# PIC32MZ2048EFM144 register map
Registers are 32-bit, access not given, reset 0x0 unless marked. A register's access mark holds for its fields unless they carry their own. Offsets are from the block's base; [hi:lo] are bit positions; {n}, {i} and the like mark numbered series; 'fields as' and 'values as' point back to an identical list.

## INT — INT peripheral
Base 0xBF810000
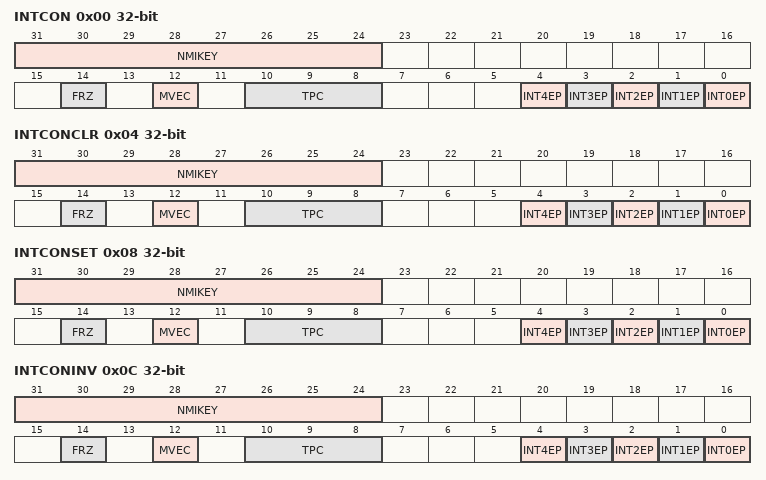
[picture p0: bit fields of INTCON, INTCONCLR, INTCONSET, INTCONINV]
0x00 INTCON
  [31:24] NMIKEY, [14] FRZ, [12] MVEC, [10:8] TPC, [n] INT{n}EP (n=0..4)
0x04 INTCONCLR
  fields as INTCON
0x08 INTCONSET
  fields as INTCON
0x0C INTCONINV
  fields as INTCON
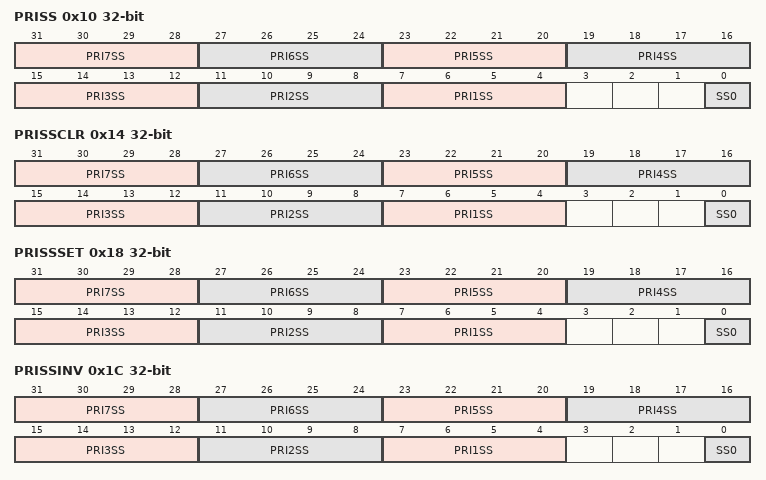
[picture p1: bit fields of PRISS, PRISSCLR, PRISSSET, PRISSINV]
0x10 PRISS
  [4n+3:4n] PRI{n}SS (n=1..7), [0] SS0
0x14 PRISSCLR
  [4n+3:4n] PRI{n}SS (n=1..7), [0] SS0
0x18 PRISSSET
  [4n+3:4n] PRI{n}SS (n=1..7), [0] SS0
0x1C PRISSINV
  [4n+3:4n] PRI{n}SS (n=1..7), [0] SS0
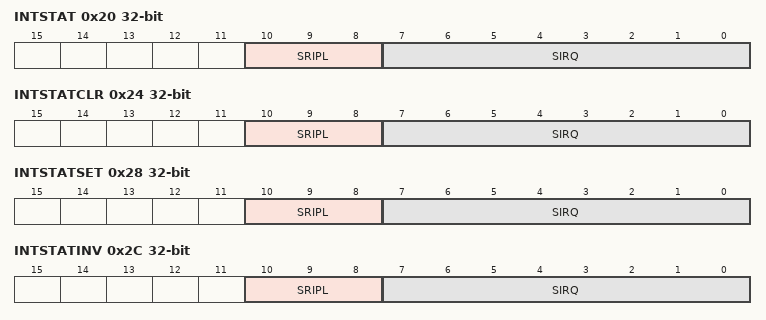
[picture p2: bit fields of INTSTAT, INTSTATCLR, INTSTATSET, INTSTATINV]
0x20 INTSTAT
  [10:8] SRIPL, [7:0] SIRQ
0x24 INTSTATCLR
  [10:8] SRIPL, [7:0] SIRQ
0x28 INTSTATSET
  [10:8] SRIPL, [7:0] SIRQ
0x2C INTSTATINV
  [10:8] SRIPL, [7:0] SIRQ
0x30 IPTMR
0x34 IPTMRCLR
  [31:0] IPTMR
0x38 IPTMRSET
  [31:0] IPTMR
0x3C IPTMRINV
  [31:0] IPTMR
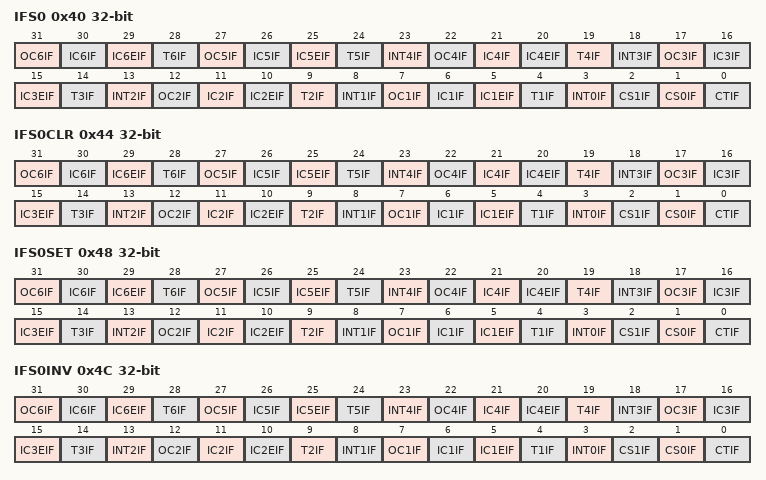
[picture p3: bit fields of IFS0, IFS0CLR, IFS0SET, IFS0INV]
0x40 IFS0
  [31] OC6IF, [30] IC6IF, [29] IC6EIF, [28] T6IF, [5n+2] OC{n}IF (n=1..5), [5n+1] IC{n}IF (n=1..5), [5n] IC{n}EIF (n=1..5), [5n-1] T{n}IF (n=1..5), [5n+3] INT{n}IF (n=0..4), [2] CS1IF, [1] CS0IF, [0] CTIF
0x44 IFS0CLR
  fields as IFS0
0x48 IFS0SET
  fields as IFS0
0x4C IFS0INV
  fields as IFS0
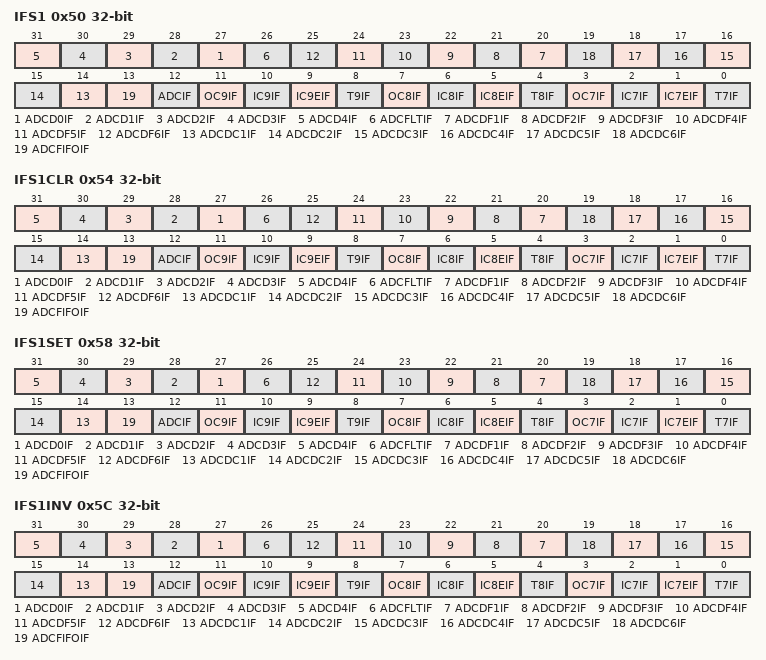
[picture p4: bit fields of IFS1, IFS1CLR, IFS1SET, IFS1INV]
0x50 IFS1
  [n+27] ADCD{n}IF (n=0..4), [26] ADCFLTIF, [n+19] ADCDF{n}IF (n=1..6), [n+13] ADCDC{n}IF (n=1..6), [13] ADCFIFOIF, [12] ADCIF, [11] OC9IF, [10] IC9IF, [9] IC9EIF, [8] T9IF, [7] OC8IF, [6] IC8IF, [5] IC8EIF, [4] T8IF, [3] OC7IF, [2] IC7IF, [1] IC7EIF, [0] T7IF
0x54 IFS1CLR
  fields as IFS1
0x58 IFS1SET
  fields as IFS1
0x5C IFS1INV
  fields as IFS1
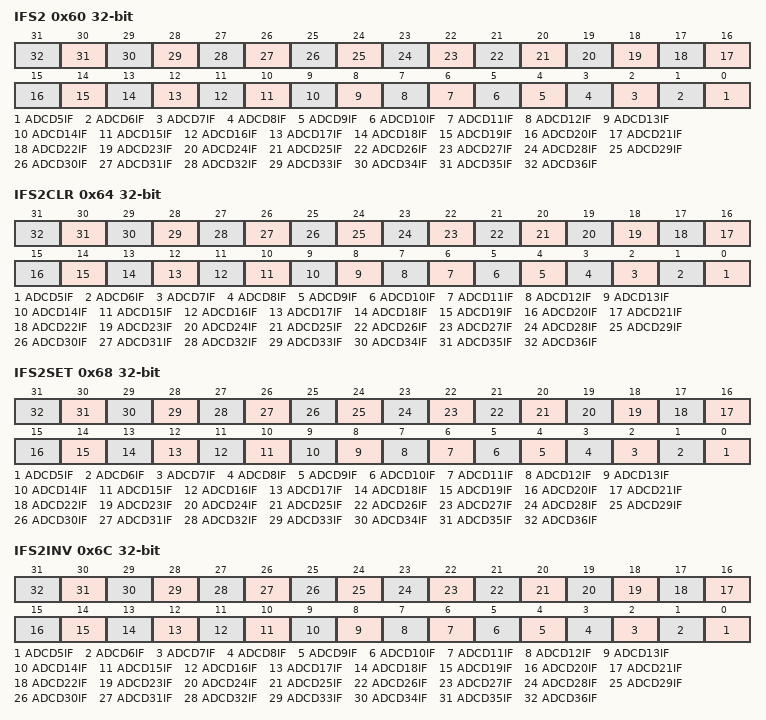
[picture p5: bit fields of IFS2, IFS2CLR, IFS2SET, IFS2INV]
0x60 IFS2
  [n-5] ADCD{n}IF (n=5..36)
0x64 IFS2CLR
  [n-5] ADCD{n}IF (n=5..36)
0x68 IFS2SET
  [n-5] ADCD{n}IF (n=5..36)
0x6C IFS2INV
  [n-5] ADCD{n}IF (n=5..36)
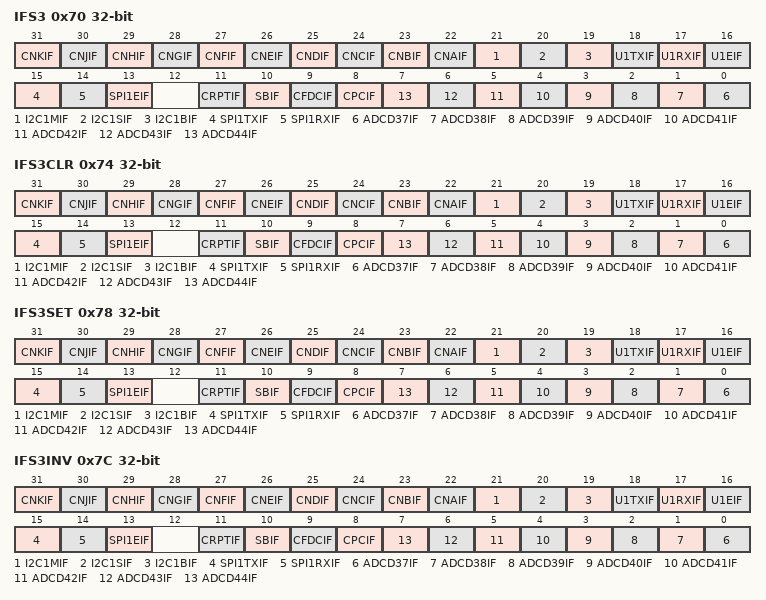
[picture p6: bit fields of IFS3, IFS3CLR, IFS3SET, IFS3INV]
0x70 IFS3
  [31] CNKIF, [30] CNJIF, [29] CNHIF, [28] CNGIF, [27] CNFIF, [26] CNEIF, [25] CNDIF, [24] CNCIF, [23] CNBIF, [22] CNAIF, [21] I2C1MIF, [20] I2C1SIF, [19] I2C1BIF, [18] U1TXIF, [17] U1RXIF, [16] U1EIF, [15] SPI1TXIF, [14] SPI1RXIF, [13] SPI1EIF, [11] CRPTIF, [10] SBIF, [9] CFDCIF, [8] CPCIF, [n-37] ADCD{n}IF (n=37..44)
0x74 IFS3CLR
  fields as IFS3
0x78 IFS3SET
  fields as IFS3
0x7C IFS3INV
  fields as IFS3
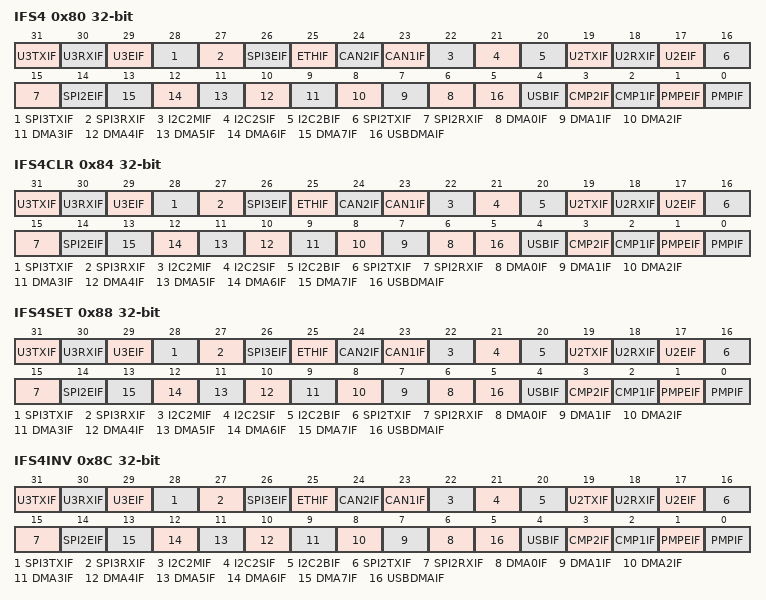
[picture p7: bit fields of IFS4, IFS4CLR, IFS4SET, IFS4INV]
0x80 IFS4
  [31] U3TXIF, [30] U3RXIF, [29] U3EIF, [28] SPI3TXIF, [27] SPI3RXIF, [26] SPI3EIF, [25] ETHIF, [24] CAN2IF, [23] CAN1IF, [22] I2C2MIF, [21] I2C2SIF, [20] I2C2BIF, [19] U2TXIF, [18] U2RXIF, [17] U2EIF, [16] SPI2TXIF, [15] SPI2RXIF, [14] SPI2EIF, [n+6] DMA{n}IF (n=0..7), [5] USBDMAIF, [4] USBIF, [3] CMP2IF, [2] CMP1IF, [1] PMPEIF, [0] PMPIF
0x84 IFS4CLR
  fields as IFS4
0x88 IFS4SET
  fields as IFS4
0x8C IFS4INV
  fields as IFS4
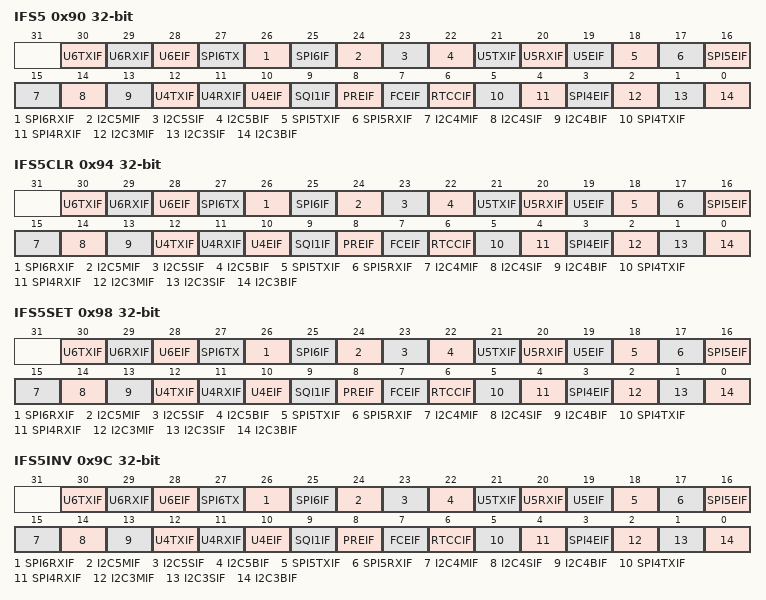
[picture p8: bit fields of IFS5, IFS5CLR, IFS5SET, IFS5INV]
0x90 IFS5
  [30] U6TXIF, [29] U6RXIF, [28] U6EIF, [27] SPI6TX, [26] SPI6RXIF, [25] SPI6IF, [24] I2C5MIF, [23] I2C5SIF, [22] I2C5BIF, [21] U5TXIF, [20] U5RXIF, [19] U5EIF, [18] SPI5TXIF, [17] SPI5RXIF, [16] SPI5EIF, [15] I2C4MIF, [14] I2C4SIF, [13] I2C4BIF, [12] U4TXIF, [11] U4RXIF, [10] U4EIF, [9] SQI1IF, [8] PREIF, [7] FCEIF, [6] RTCCIF, [5] SPI4TXIF, [4] SPI4RXIF, [3] SPI4EIF, [2] I2C3MIF, [1] I2C3SIF, [0] I2C3BIF
0x94 IFS5CLR
  fields as IFS5
0x98 IFS5SET
  fields as IFS5
0x9C IFS5INV
  fields as IFS5
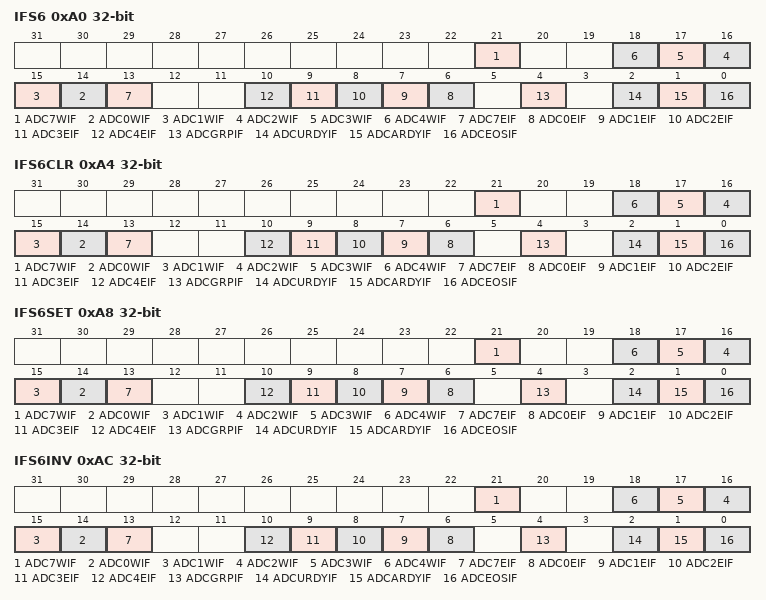
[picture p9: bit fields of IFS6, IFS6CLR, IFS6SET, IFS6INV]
0xA0 IFS6
  [21] ADC7WIF, [n+14] ADC{n}WIF (n=0..4), [13] ADC7EIF, [n+6] ADC{n}EIF (n=0..4), [4] ADCGRPIF, [2] ADCURDYIF, [1] ADCARDYIF, [0] ADCEOSIF
0xA4 IFS6CLR
  fields as IFS6
0xA8 IFS6SET
  fields as IFS6
0xAC IFS6INV
  fields as IFS6
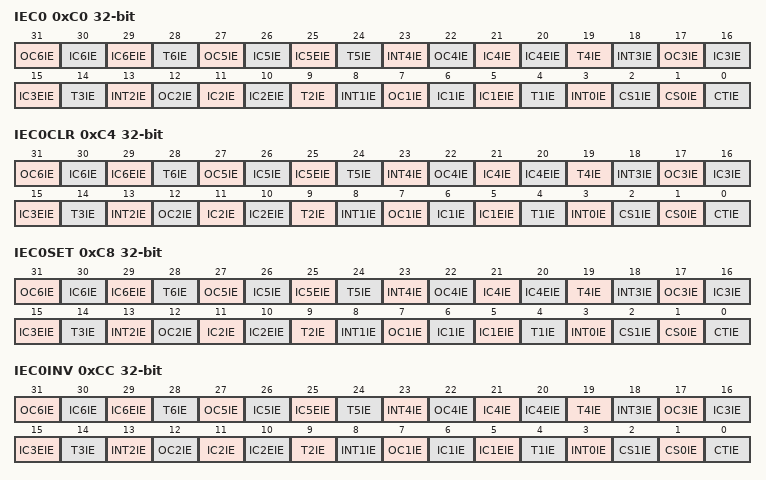
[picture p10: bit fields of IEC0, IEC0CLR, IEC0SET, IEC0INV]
0xC0 IEC0
  [31] OC6IE, [30] IC6IE, [29] IC6EIE, [28] T6IE, [5n+2] OC{n}IE (n=1..5), [5n+1] IC{n}IE (n=1..5), [5n] IC{n}EIE (n=1..5), [5n-1] T{n}IE (n=1..5), [5n+3] INT{n}IE (n=0..4), [2] CS1IE, [1] CS0IE, [0] CTIE
0xC4 IEC0CLR
  fields as IEC0
0xC8 IEC0SET
  fields as IEC0
0xCC IEC0INV
  fields as IEC0
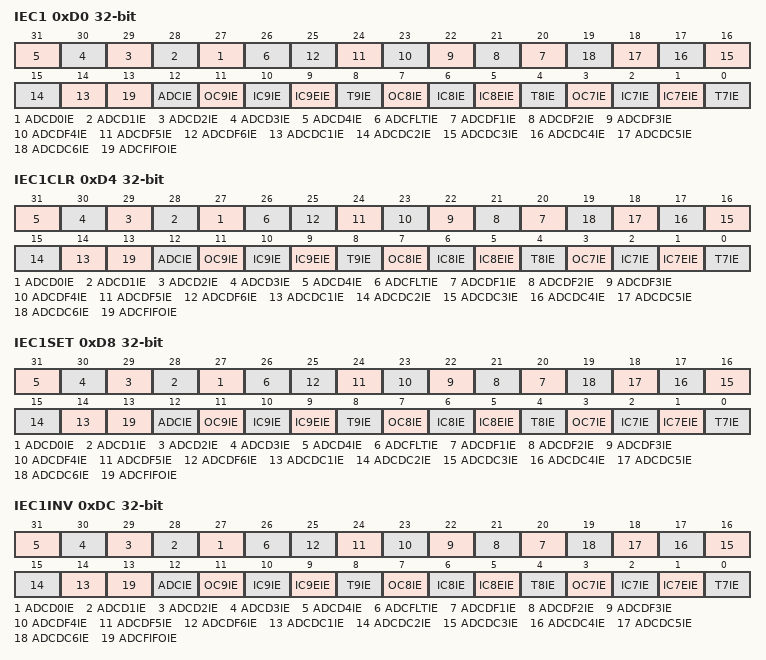
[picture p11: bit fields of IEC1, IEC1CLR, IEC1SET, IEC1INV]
0xD0 IEC1
  [n+27] ADCD{n}IE (n=0..4), [26] ADCFLTIE, [n+19] ADCDF{n}IE (n=1..6), [n+13] ADCDC{n}IE (n=1..6), [13] ADCFIFOIE, [12] ADCIE, [11] OC9IE, [10] IC9IE, [9] IC9EIE, [8] T9IE, [7] OC8IE, [6] IC8IE, [5] IC8EIE, [4] T8IE, [3] OC7IE, [2] IC7IE, [1] IC7EIE, [0] T7IE
0xD4 IEC1CLR
  fields as IEC1
0xD8 IEC1SET
  fields as IEC1
0xDC IEC1INV
  fields as IEC1
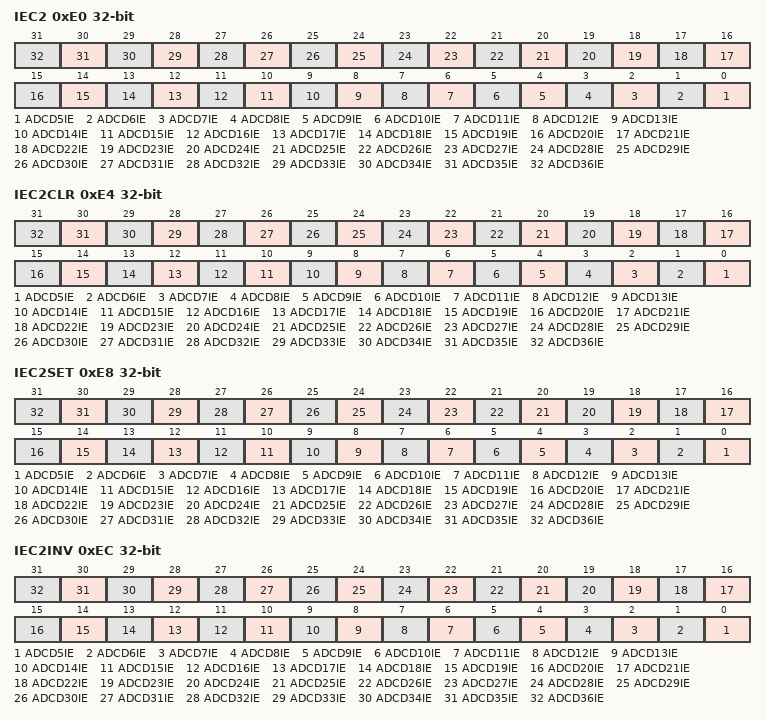
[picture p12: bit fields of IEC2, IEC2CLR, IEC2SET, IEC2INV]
0xE0 IEC2
  [n-5] ADCD{n}IE (n=5..36)
0xE4 IEC2CLR
  [n-5] ADCD{n}IE (n=5..36)
0xE8 IEC2SET
  [n-5] ADCD{n}IE (n=5..36)
0xEC IEC2INV
  [n-5] ADCD{n}IE (n=5..36)
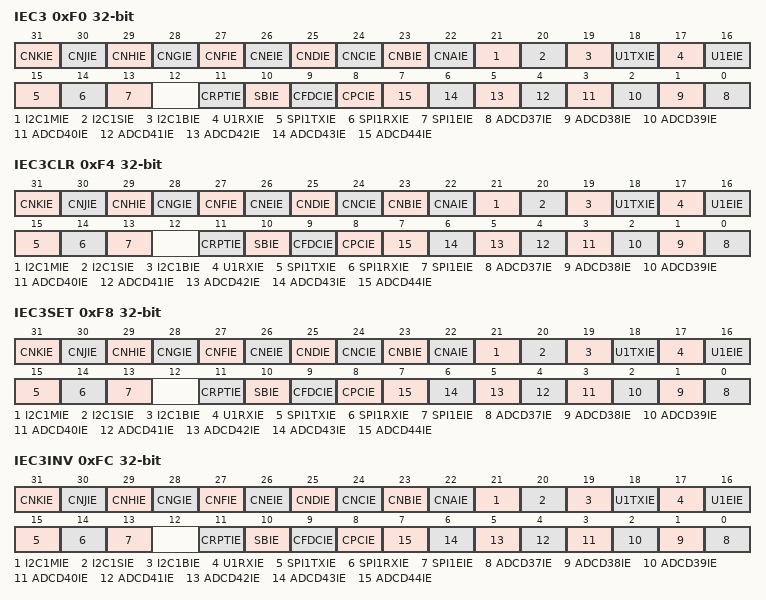
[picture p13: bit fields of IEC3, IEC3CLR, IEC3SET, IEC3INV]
0xF0 IEC3
  [31] CNKIE, [30] CNJIE, [29] CNHIE, [28] CNGIE, [27] CNFIE, [26] CNEIE, [25] CNDIE, [24] CNCIE, [23] CNBIE, [22] CNAIE, [21] I2C1MIE, [20] I2C1SIE, [19] I2C1BIE, [18] U1TXIE, [17] U1RXIE, [16] U1EIE, [15] SPI1TXIE, [14] SPI1RXIE, [13] SPI1EIE, [11] CRPTIE, [10] SBIE, [9] CFDCIE, [8] CPCIE, [n-37] ADCD{n}IE (n=37..44)
0xF4 IEC3CLR
  fields as IEC3
0xF8 IEC3SET
  fields as IEC3
0xFC IEC3INV
  fields as IEC3
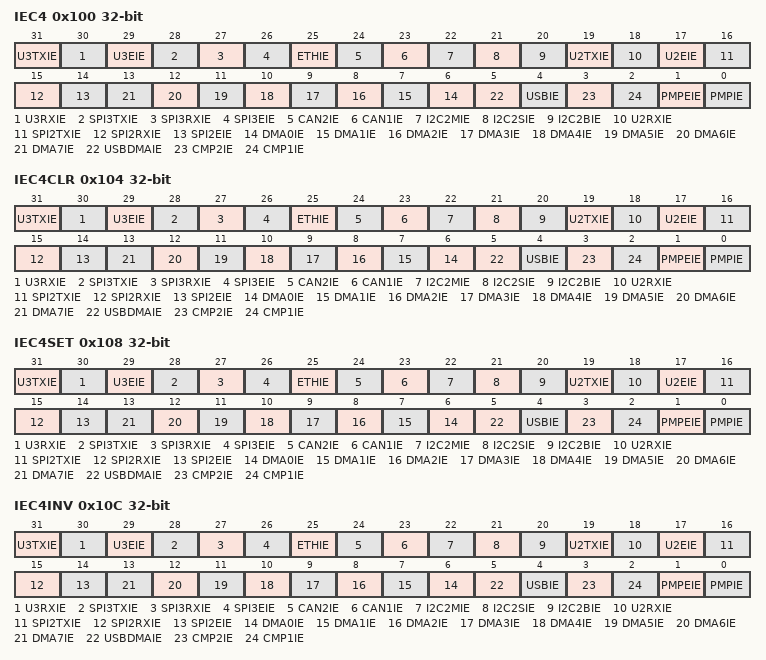
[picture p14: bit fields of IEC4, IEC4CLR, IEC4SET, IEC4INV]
0x100 IEC4
  [31] U3TXIE, [30] U3RXIE, [29] U3EIE, [28] SPI3TXIE, [27] SPI3RXIE, [26] SPI3EIE, [25] ETHIE, [24] CAN2IE, [23] CAN1IE, [22] I2C2MIE, [21] I2C2SIE, [20] I2C2BIE, [19] U2TXIE, [18] U2RXIE, [17] U2EIE, [16] SPI2TXIE, [15] SPI2RXIE, [14] SPI2EIE, [n+6] DMA{n}IE (n=0..7), [5] USBDMAIE, [4] USBIE, [3] CMP2IE, [2] CMP1IE, [1] PMPEIE, [0] PMPIE
0x104 IEC4CLR
  fields as IEC4
0x108 IEC4SET
  fields as IEC4
0x10C IEC4INV
  fields as IEC4
0x110 IEC5
  [30] U6TXIE, [29] U6RXIE, [28] U6EIE, [27] SPI6TXIE, [26] SPI6RXIE, [25] SPI6IE, [24] I2C5MIE, [23] I2C5SIE, [22] I2C5BIE, [21] U5TXIE, [20] U5RXIE, [19] U5EIE, [18] SPI5TXIE, [17] SPI5RXIE, [16] SPI5EIE, [15] I2C4MIE, [14] I2C4SIE, [13] I2C4BIE, [12] U4TXIE, [11] U4RXIE, [10] U4EIE, [9] SQI1IE, [8] PREIE, [7] FCEIE, [6] RTCCIE, [5] SPI4TXIE, [4] SPI4RXIE, [3] SPI4EIE, [2] I2C3MIE, [1] I2C3SIE, [0] I2C3BIE
0x114 IEC5CLR
  fields as IEC5
0x118 IEC5SET
  fields as IEC5
0x11C IEC5INV
  fields as IEC5
0x120 IEC6
  [21] ADC7WIE, [n+14] ADC{n}WIE (n=0..4), [13] ADC7EIE, [n+6] ADC{n}EIE (n=0..4), [4] ADCGRPIE, [2] ADCURDYIE, [1] ADCARDYIE, [0] ADCEOSIE
0x124 IEC6CLR
  fields as IEC6
0x128 IEC6SET
  fields as IEC6
0x12C IEC6INV
  fields as IEC6
0x140 IPC0
  [28:26] INT0IP, [25:24] INT0IS, [20:18] CS1IP, [17:16] CS1IS, [12:10] CS0IP, [9:8] CS0IS, [4:2] CTIP, [1:0] CTIS
0x144 IPC0CLR
  fields as IPC0
0x148 IPC0SET
  fields as IPC0
0x14C IPC0INV
  fields as IPC0
0x150 IPC1
  [28:26] OC1IP, [25:24] OC1IS, [20:18] IC1IP, [17:16] IC1IS, [12:10] IC1EIP, [9:8] IC1EIS, [4:2] T1IP, [1:0] T1IS
0x154 IPC1CLR
  fields as IPC1
0x158 IPC1SET
  fields as IPC1
0x15C IPC1INV
  fields as IPC1
0x160 IPC2
  [28:26] IC2IP, [25:24] IC2IS, [20:18] IC2EIP, [17:16] IC2EIS, [12:10] T2IP, [9:8] T2IS, [4:2] INT1IP, [1:0] INT1IS
0x164 IPC2CLR
  fields as IPC2
0x168 IPC2SET
  fields as IPC2
0x16C IPC2INV
  fields as IPC2
0x170 IPC3
  [28:26] IC3EIP, [25:24] IC3EIS, [20:18] T3IP, [17:16] T3IS, [12:10] INT2IP, [9:8] INT2IS, [4:2] OC2IP, [1:0] OC2IS
0x174 IPC3CLR
  fields as IPC3
0x178 IPC3SET
  fields as IPC3
0x17C IPC3INV
  fields as IPC3
0x180 IPC4
  [28:26] T4IP, [25:24] T4IS, [20:18] INT3IP, [17:16] INT3IS, [12:10] OC3IP, [9:8] OC3IS, [4:2] IC3IP, [1:0] IC3IS
0x184 IPC4CLR
  fields as IPC4
0x188 IPC4SET
  fields as IPC4
0x18C IPC4INV
  fields as IPC4
0x190 IPC5
  [28:26] INT4IP, [25:24] INT4IS, [20:18] OC4IP, [17:16] OC4IS, [12:10] IC4IP, [9:8] IC4IS, [4:2] IC4EIP, [1:0] IC4EIS
0x194 IPC5CLR
  fields as IPC5
0x198 IPC5SET
  fields as IPC5
0x19C IPC5INV
  fields as IPC5
{0x140+0x10*i} IPC{i} (i=6..10)
  [28:26] OC{i-1}IP, [25:24] OC{i-1}IS, [20:18] IC{i-1}IP, [17:16] IC{i-1}IS, [12:10] IC{i-1}EIP, [9:8] IC{i-1}EIS, [4:2] T{i-1}IP, [1:0] T{i-1}IS
{0x144+0x10*i} IPC{i}CLR (i=6..10)
  fields as IPC6
{0x148+0x10*i} IPC{i}SET (i=6..10)
  fields as IPC6
{0x14C+0x10*i} IPC{i}INV (i=6..10)
  fields as IPC6
0x1F0 IPC11
  [28:26] ADCDC2IP, [25:24] ADCDC2IS, [20:18] ADCDC1IP, [17:16] ADCDC1IS, [12:10] ADCFIFOIP, [9:8] ADCFIFOIS, [4:2] ADCIP, [1:0] ADCIS
0x1F4 IPC11CLR
  fields as IPC11
0x1F8 IPC11SET
  fields as IPC11
0x1FC IPC11INV
  fields as IPC11
0x200 IPC12
  [8n-20:8n-22] ADCDC{n}IP (n=3..6), [8n-23:8n-24] ADCDC{n}IS (n=3..6)
0x204 IPC12CLR
  [8n-20:8n-22] ADCDC{n}IP (n=3..6), [8n-23:8n-24] ADCDC{n}IS (n=3..6)
0x208 IPC12SET
  [8n-20:8n-22] ADCDC{n}IP (n=3..6), [8n-23:8n-24] ADCDC{n}IS (n=3..6)
0x20C IPC12INV
  [8n-20:8n-22] ADCDC{n}IP (n=3..6), [8n-23:8n-24] ADCDC{n}IS (n=3..6)
0x210 IPC13
  [8n-4:8n-6] ADCDF{n}IP (n=1..4), [8n-7:8n-8] ADCDF{n}IS (n=1..4)
0x214 IPC13CLR
  [8n-4:8n-6] ADCDF{n}IP (n=1..4), [8n-7:8n-8] ADCDF{n}IS (n=1..4)
0x218 IPC13SET
  [8n-4:8n-6] ADCDF{n}IP (n=1..4), [8n-7:8n-8] ADCDF{n}IS (n=1..4)
0x21C IPC13INV
  [8n-4:8n-6] ADCDF{n}IP (n=1..4), [8n-7:8n-8] ADCDF{n}IS (n=1..4)
0x220 IPC14
  [28:26] ADCD0IP, [25:24] ADCD0IS, [20:18] ADCFLTIP, [17:16] ADCFLTIS, [12:10] ADCDF6IP, [9:8] ADCDF6IS, [4:2] ADCDF5IP, [1:0] ADCDF5IS
0x224 IPC14CLR
  fields as IPC14
0x228 IPC14SET
  fields as IPC14
0x22C IPC14INV
  fields as IPC14
0x230 IPC15
  [8n-4:8n-6] ADCD{n}IP (n=1..4), [8n-7:8n-8] ADCD{n}IS (n=1..4)
0x234 IPC15CLR
  [8n-4:8n-6] ADCD{n}IP (n=1..4), [8n-7:8n-8] ADCD{n}IS (n=1..4)
0x238 IPC15SET
  [8n-4:8n-6] ADCD{n}IP (n=1..4), [8n-7:8n-8] ADCD{n}IS (n=1..4)
0x23C IPC15INV
  [8n-4:8n-6] ADCD{n}IP (n=1..4), [8n-7:8n-8] ADCD{n}IS (n=1..4)
0x240 IPC16
  [8n-36:8n-38] ADCD{n}IP (n=5..8), [8n-39:8n-40] ADCD{n}IS (n=5..8)
0x244 IPC16CLR
  [8n-36:8n-38] ADCD{n}IP (n=5..8), [8n-39:8n-40] ADCD{n}IS (n=5..8)
0x248 IPC16SET
  [8n-36:8n-38] ADCD{n}IP (n=5..8), [8n-39:8n-40] ADCD{n}IS (n=5..8)
0x24C IPC16INV
  [8n-36:8n-38] ADCD{n}IP (n=5..8), [8n-39:8n-40] ADCD{n}IS (n=5..8)
0x250 IPC17
  [8n-68:8n-70] ADCD{n}IP (n=9..12), [8n-71:8n-72] ADCD{n}IS (n=9..12)
0x254 IPC17CLR
  [8n-68:8n-70] ADCD{n}IP (n=9..12), [8n-71:8n-72] ADCD{n}IS (n=9..12)
0x258 IPC17SET
  [8n-68:8n-70] ADCD{n}IP (n=9..12), [8n-71:8n-72] ADCD{n}IS (n=9..12)
0x25C IPC17INV
  [8n-68:8n-70] ADCD{n}IP (n=9..12), [8n-71:8n-72] ADCD{n}IS (n=9..12)
0x260 IPC18
  [8n-100:8n-102] ADCD{n}IP (n=13..16), [8n-103:8n-104] ADCD{n}IS (n=13..16)
0x264 IPC18CLR
  fields as IPC18
0x268 IPC18SET
  fields as IPC18
0x26C IPC18INV
  fields as IPC18
0x270 IPC19
  [8n-132:8n-134] ADCD{n}IP (n=17..20), [8n-135:8n-136] ADCD{n}IS (n=17..20)
0x274 IPC19CLR
  fields as IPC19
0x278 IPC19SET
  fields as IPC19
0x27C IPC19INV
  fields as IPC19
0x280 IPC20
  [8n-164:8n-166] ADCD{n}IP (n=21..24), [8n-167:8n-168] ADCD{n}IS (n=21..24)
0x284 IPC20CLR
  fields as IPC20
0x288 IPC20SET
  fields as IPC20
0x28C IPC20INV
  fields as IPC20
0x290 IPC21
  [8n-196:8n-198] ADCD{n}IP (n=25..28), [8n-199:8n-200] ADCD{n}IS (n=25..28)
0x294 IPC21CLR
  fields as IPC21
0x298 IPC21SET
  fields as IPC21
0x29C IPC21INV
  fields as IPC21
0x2A0 IPC22
  [8n-228:8n-230] ADCD{n}IP (n=29..32), [8n-231:8n-232] ADCD{n}IS (n=29..32)
0x2A4 IPC22CLR
  fields as IPC22
0x2A8 IPC22SET
  fields as IPC22
0x2AC IPC22INV
  fields as IPC22
0x2B0 IPC23
  [8n-260:8n-262] ADCD{n}IP (n=33..36), [8n-263:8n-264] ADCD{n}IS (n=33..36)
0x2B4 IPC23CLR
  fields as IPC23
0x2B8 IPC23SET
  fields as IPC23
0x2BC IPC23INV
  fields as IPC23
0x2C0 IPC24
  [8n-292:8n-294] ADCD{n}IP (n=37..40), [8n-295:8n-296] ADCD{n}IS (n=37..40)
0x2C4 IPC24CLR
  fields as IPC24
0x2C8 IPC24SET
  fields as IPC24
0x2CC IPC24INV
  fields as IPC24
0x2D0 IPC25
  [8n-324:8n-326] ADCD{n}IP (n=41..44), [8n-327:8n-328] ADCD{n}IS (n=41..44)
0x2D4 IPC25CLR
  fields as IPC25
0x2D8 IPC25SET
  fields as IPC25
0x2DC IPC25INV
  fields as IPC25
0x2E0 IPC26
  [28:26] CRPTIP, [25:24] CRPTIS, [20:18] SBIP, [17:16] SBIS, [12:10] CFDCIP, [9:8] CFDCIS, [4:2] CPCIP, [1:0] CPCIS
0x2E4 IPC26CLR
  fields as IPC26
0x2E8 IPC26SET
  fields as IPC26
0x2EC IPC26INV
  fields as IPC26
0x2F0 IPC27
  [28:26] SPI1TXIP, [25:24] SPI1TXIS, [20:18] SPI1RXIP, [17:16] SPI1RXIS, [12:10] SPI1EIP, [9:8] SPI1EIS
0x2F4 IPC27CLR
  fields as IPC27
0x2F8 IPC27SET
  fields as IPC27
0x2FC IPC27INV
  fields as IPC27
0x300 IPC28
  [28:26] I2C1BIP, [25:24] I2C1BIS, [20:18] U1TXIP, [17:16] U1TXIS, [12:10] U1RXIP, [9:8] U1RXIS, [4:2] U1EIP, [1:0] U1EIS
0x304 IPC28CLR
  fields as IPC28
0x308 IPC28SET
  fields as IPC28
0x30C IPC28INV
  fields as IPC28
0x310 IPC29
  [28:26] CNBIP, [25:24] CNBIS, [20:18] CNAIP, [17:16] CNAIS, [12:10] I2C1MIP, [9:8] I2C1MIS, [4:2] I2C1SIP, [1:0] I2C1SIS
0x314 IPC29CLR
  fields as IPC29
0x318 IPC29SET
  fields as IPC29
0x31C IPC29INV
  fields as IPC29
0x320 IPC30
  [28:26] CNFIP, [25:24] CNFIS, [20:18] CNEIP, [17:16] CNEIS, [12:10] CNDIP, [9:8] CNDIS, [4:2] CNCIP, [1:0] CNCIS
0x324 IPC30CLR
  fields as IPC30
0x328 IPC30SET
  fields as IPC30
0x32C IPC30INV
  fields as IPC30
0x330 IPC31
  [28:26] CNKIP, [25:24] CNKIS, [20:18] CNJIP, [17:16] CNJIS, [12:10] CNHIP, [9:8] CNHIS, [4:2] CNGIP, [1:0] CNGIS
0x334 IPC31CLR
  fields as IPC31
0x338 IPC31SET
  fields as IPC31
0x33C IPC31INV
  fields as IPC31
0x340 IPC32
  [28:26] CMP2IP, [25:24] CMP2IS, [20:18] CMP1IP, [17:16] CMP1IS, [12:10] PMPEIP, [9:8] PMPEIS, [4:2] PMPIP, [1:0] PMPIS
0x344 IPC32CLR
  fields as IPC32
0x348 IPC32SET
  fields as IPC32
0x34C IPC32INV
  fields as IPC32
0x350 IPC33
  [28:26] DMA1IP, [25:24] DMA1IS, [20:18] DMA0IP, [17:16] DMA0IS, [12:10] USBDMAIP, [9:8] USBDMAIS, [4:2] USBIP, [1:0] USBIS
0x354 IPC33CLR
  fields as IPC33
0x358 IPC33SET
  fields as IPC33
0x35C IPC33INV
  fields as IPC33
0x360 IPC34
  [8n-12:8n-14] DMA{n}IP (n=2..5), [8n-15:8n-16] DMA{n}IS (n=2..5)
0x364 IPC34CLR
  [8n-12:8n-14] DMA{n}IP (n=2..5), [8n-15:8n-16] DMA{n}IS (n=2..5)
0x368 IPC34SET
  [8n-12:8n-14] DMA{n}IP (n=2..5), [8n-15:8n-16] DMA{n}IS (n=2..5)
0x36C IPC34INV
  [8n-12:8n-14] DMA{n}IP (n=2..5), [8n-15:8n-16] DMA{n}IS (n=2..5)
0x370 IPC35
  [28:26] SPI2RXIP, [25:24] SPI2RXIS, [20:18] SPI2EIP, [17:16] SPI2EIS, [12:10] DMA7IP, [9:8] DMA7IS, [4:2] DMA6IP, [1:0] DMA6IS
0x374 IPC35CLR
  fields as IPC35
0x378 IPC35SET
  fields as IPC35
0x37C IPC35INV
  fields as IPC35
0x380 IPC36
  [28:26] U2TXIP, [25:24] U2TXIS, [20:18] U2RXIP, [17:16] U2RXIS, [12:10] U2EIP, [9:8] U2EIS, [4:2] SPI2TXIP, [1:0] SPI2TXIS
0x384 IPC36CLR
  fields as IPC36
0x388 IPC36SET
  fields as IPC36
0x38C IPC36INV
  fields as IPC36
0x390 IPC37
  [28:26] CAN1IP, [25:24] CAN1IS, [20:18] I2C2MIP, [17:16] I2C2MIS, [12:10] I2C2SIP, [9:8] I2C2SIS, [4:2] I2C2BIP, [1:0] I2C2BIS
0x394 IPC37CLR
  fields as IPC37
0x398 IPC37SET
  fields as IPC37
0x39C IPC37INV
  fields as IPC37
0x3A0 IPC38
  [28:26] SPI3RXIP, [25:24] SPI3RXIS, [20:18] SPI3EIP, [17:16] SPI3EIS, [12:10] ETHIP, [9:8] ETHIS, [4:2] CAN2IP, [1:0] CAN2IS
0x3A4 IPC38CLR
  fields as IPC38
0x3A8 IPC38SET
  fields as IPC38
0x3AC IPC38INV
  fields as IPC38
0x3B0 IPC39
  [28:26] U3TXIP, [25:24] U3TXIS, [20:18] U3RXIP, [17:16] U3RXIS, [12:10] U3EIP, [9:8] U3EIS, [4:2] SPI3TXIP, [1:0] SPI3TXIS
0x3B4 IPC39CLR
  fields as IPC39
0x3B8 IPC39SET
  fields as IPC39
0x3BC IPC39INV
  fields as IPC39
0x3C0 IPC40
  [28:26] SPI4EIP, [25:24] SPI4EIS, [20:18] I2C3MIP, [17:16] I2C3MIS, [12:10] I2C3SIP, [9:8] I2C3SIS, [4:2] I2C3BIP, [1:0] I2C3BIS
0x3C4 IPC40CLR
  fields as IPC40
0x3C8 IPC40SET
  fields as IPC40
0x3CC IPC40INV
  fields as IPC40
0x3D0 IPC41
  [28:26] FCEIP, [25:24] FCEIS, [20:18] RTCCIP, [17:16] RTCCIS, [12:10] SPI4TXIP, [9:8] SPI4TXIS, [4:2] SPI4RXIP, [1:0] SPI4RXIS
0x3D4 IPC41CLR
  fields as IPC41
0x3D8 IPC41SET
  fields as IPC41
0x3DC IPC41INV
  fields as IPC41
0x3E0 IPC42
  [28:26] U4RXIP, [25:24] U4RXIS, [20:18] U4EIP, [17:16] U4EIS, [12:10] SQI1IP, [9:8] SQI1IS, [4:2] PREIP, [1:0] PREIS
0x3E4 IPC42CLR
  fields as IPC42
0x3E8 IPC42SET
  fields as IPC42
0x3EC IPC42INV
  fields as IPC42
0x3F0 IPC43
  [28:26] I2C4MIP, [25:24] I2C4MIS, [20:18] I2C4SIP, [17:16] I2C4SIS, [12:10] I2C4BIP, [9:8] I2C4BIS, [4:2] U4TXIP, [1:0] U4TXIS
0x3F4 IPC43CLR
  fields as IPC43
0x3F8 IPC43SET
  fields as IPC43
0x3FC IPC43INV
  fields as IPC43
0x400 IPC44
  [28:26] U5EIP, [25:24] U5EIS, [20:18] SPI5TXIP, [17:16] SPI5TXIS, [12:10] SPI5RXIP, [9:8] SPI5RXIS, [4:2] SPI5EIP, [1:0] SPI5EIS
0x404 IPC44CLR
  fields as IPC44
0x408 IPC44SET
  fields as IPC44
0x40C IPC44INV
  fields as IPC44
0x410 IPC45
  [28:26] I2C5SIP, [25:24] I2C5SIS, [20:18] I2C5BIP, [17:16] I2C5BIS, [12:10] U5TXIP, [9:8] U5TXIS, [4:2] U5RXIP, [1:0] U5RXIS
0x414 IPC45CLR
  fields as IPC45
0x418 IPC45SET
  fields as IPC45
0x41C IPC45INV
  fields as IPC45
0x420 IPC46
  [28:26] SPI6TXIP, [25:24] SPI6TXIS, [20:18] SPI6RXIP, [17:16] SPI6RXIS, [12:10] SPI6EIP, [9:8] SPI6EIS, [4:2] I2C5MIP, [1:0] I2C5MIS
0x424 IPC46CLR
  fields as IPC46
0x428 IPC46SET
  fields as IPC46
0x42C IPC46INV
  fields as IPC46
0x430 IPC47
  [20:18] U6TXIP, [17:16] U6TXIS, [12:10] U6RXIP, [9:8] U6RXIS, [4:2] U6EIP, [1:0] U6EIS
0x434 IPC47CLR
  fields as IPC47
0x438 IPC47SET
  fields as IPC47
0x43C IPC47INV
  fields as IPC47
0x440 IPC48
  [20:18] ADCURDYIP, [17:16] ADCURDYIS, [12:10] ADCARDYIP, [9:8] ADCARDYIS, [4:2] ADCEOSIP, [1:0] ADCEOSIS
0x444 IPC48CLR
  fields as IPC48
0x448 IPC48SET
  fields as IPC48
0x44C IPC48INV
  fields as IPC48
0x450 IPC49
  [28:26] ADC1EIP, [25:24] ADC1EIS, [20:18] ADC0EIP, [17:16] ADC0EIS, [4:2] ADCGRPIP, [1:0] ADCGRPIS
0x454 IPC49CLR
  fields as IPC49
0x458 IPC49SET
  fields as IPC49
0x45C IPC49INV
  fields as IPC49
0x460 IPC50
  [20:18] ADC4EIP, [17:16] ADC4EIS, [12:10] ADC3EIP, [9:8] ADC3EIS, [4:2] ADC2EIP, [1:0] ADC2EIS
0x464 IPC50CLR
  fields as IPC50
0x468 IPC50SET
  fields as IPC50
0x46C IPC50INV
  fields as IPC50
0x470 IPC51
  [28:26] ADC1WIP, [25:24] ADC1WIS, [20:18] ADC0WIP, [17:16] ADC0WIS, [12:10] ADC7EIP, [9:8] ADC7EIS
0x474 IPC51CLR
  fields as IPC51
0x478 IPC51SET
  fields as IPC51
0x47C IPC51INV
  fields as IPC51
0x480 IPC52
  [20:18] ADC4WIP, [17:16] ADC4WIS, [12:10] ADC3WIP, [9:8] ADC3WIS, [4:2] ADC2WIP, [1:0] ADC2WIS
0x484 IPC52CLR
  fields as IPC52
0x488 IPC52SET
  fields as IPC52
0x48C IPC52INV
  fields as IPC52
0x490 IPC53
  [12:10] ADC7WIP, [9:8] ADC7WIS
0x494 IPC53CLR
  [12:10] ADC7WIP, [9:8] ADC7WIS
0x498 IPC53SET
  [12:10] ADC7WIP, [9:8] ADC7WIS
0x49C IPC53INV
  [12:10] ADC7WIP, [9:8] ADC7WIS
{0x540+4i} OFF{i:03} (i=0..107)
  [17:1] VOFF
{0x540+4i} OFF{i} (i=109..190)
  [17:1] VOFF
0x840 OFF190
  [17:1] VOFF
0x844 OFF190
  [17:1] VOFF
0x848 OFF190
  [17:1] VOFF
0x850 OFF190
  [17:1] VOFF
0x858 OFF190
  [17:1] VOFF
0x85C OFF190
  [17:1] VOFF
0x860 OFF190
  [17:1] VOFF
0x864 OFF190
  [17:1] VOFF
0x868 OFF190
  [17:1] VOFF
0x874 OFF190
  [17:1] VOFF
0x878 OFF190
  [17:1] VOFF
0x87C OFF190
  [17:1] VOFF
0x880 OFF190
  [17:1] VOFF
0x884 OFF190
  [17:1] VOFF
0x888 OFF190
  [17:1] VOFF
0x894 OFF190
  [17:1] VOFF
0x1000 DMACON
  [15] ON, [14] FRZ, [12] SUSPEND, [11] DMABUSY
0x1004 DMACONCLR
  [15] ON, [14] FRZ, [12] SUSPEND, [11] DMABUSY
0x1008 DMACONSET
  [15] ON, [14] FRZ, [12] SUSPEND, [11] DMABUSY
0x100C DMACONINV
  [15] ON, [14] FRZ, [12] SUSPEND, [11] DMABUSY
0x1010 DMASTAT
  [31] RDWR, [2:0] DMACH
0x1014 DMASTATCLR
  [31] RDWR, [2:0] DMACH
0x1018 DMASTATSET
  [31] RDWR, [2:0] DMACH
0x101C DMASTATINV
  [31] RDWR, [2:0] DMACH
0x1020 DMAADDR
0x1024 DMAADDRCLR
  [31:0] DMAADDR
0x1028 DMAADDRSET
  [31:0] DMAADDR
0x102C DMAADDRINV
  [31:0] DMAADDR
0x1030 DCRCCON
  [29:28] BYTO, [27] WBO, [24] BITO, [12:8] PLEN, [7] CRCEN, [6] CRCAPP, [5] CRCTYP, [2:0] CRCCH
0x1034 DCRCCONCLR
  fields as DCRCCON
0x1038 DCRCCONSET
  fields as DCRCCON
0x103C DCRCCONINV
  fields as DCRCCON
0x1040 DCRCDATA
0x1044 DCRCDATACLR
  [31:0] DCRCDATA
0x1048 DCRCDATASET
  [31:0] DCRCDATA
0x104C DCRCDATAINV
  [31:0] DCRCDATA
0x1050 DCRCXOR
0x1054 DCRCXORCLR
  [31:0] DCRCXOR
0x1058 DCRCXORSET
  [31:0] DCRCXOR
0x105C DCRCXORINV
  [31:0] DCRCXOR
